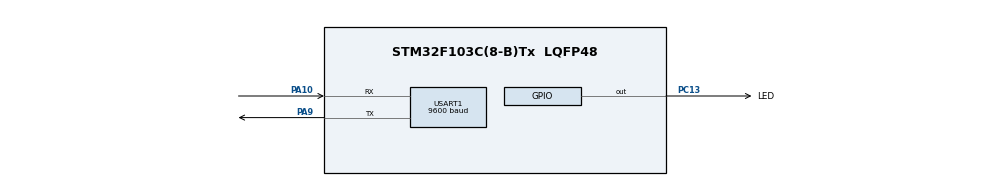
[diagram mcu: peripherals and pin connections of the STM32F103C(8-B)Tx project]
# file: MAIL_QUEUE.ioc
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FREERTOS.Queues01=Queue01,16,uint16_t,0,Dynamic,NULL,NULL
FREERTOS.Tasks01=defaultTask,0,128,StartDefaultTask,Default,NULL,Dynamic,NULL,NULL
FREERTOS.configUSE_NEWLIB_REENTRANT=1
Mcu.Family=STM32F1
Mcu.Name=STM32F103C(8-B)Tx
Mcu.Package=LQFP48
NVIC.PriorityGroup=NVIC_PRIORITYGROUP_4
NVIC.TIM4_IRQn=true\:15\:0\:false\:false\:true\:false\:false\:true\:true
NVIC.TimeBase=TIM4_IRQn
NVIC.TimeBaseIP=TIM4
NVIC.USART1_IRQn=true\:5\:0\:false\:false\:true\:true\:true\:true\:true
PA10.Mode=Asynchronous
PA10.Signal=USART1_RX
PA13.Mode=Serial_Wire
PA13.Signal=SYS_JTMS-SWDIO
PA14.Mode=Serial_Wire
PA14.Signal=SYS_JTCK-SWCLK
PA9.Mode=Asynchronous
PA9.Signal=USART1_TX
PC13-TAMPER-RTC.GPIO_Label=LED
PC13-TAMPER-RTC.Signal=GPIO_Output
PD0-OSC_IN.Mode=HSE-External-Oscillator
PD0-OSC_IN.Signal=RCC_OSC_IN
PD1-OSC_OUT.Mode=HSE-External-Oscillator
PD1-OSC_OUT.Signal=RCC_OSC_OUT
ProjectManager.HeapSize=0x200
ProjectManager.StackSize=0x400
ProjectManager.TargetToolchain=STM32CubeIDE
RCC.APB1Freq_Value=8000000
RCC.APB2Freq_Value=8000000
USART1.BaudRate=9600
USART1.VirtualMode=VM_ASYNC
VP_FREERTOS_VS_CMSIS_V1.Mode=CMSIS_V1
VP_SYS_VS_tim4.Mode=TIM4
board=custom

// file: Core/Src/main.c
/* USER CODE BEGIN Header */
/**
 ******************************************************************************
 * @file           : main.c
 * @brief          : Main program body
 ******************************************************************************
 * @attention
 *
 * Copyright (c) 2023 STMicroelectronics.
 * All rights reserved.
 *
 * This software is licensed under terms that can be found in the LICENSE file
 * in the root directory of this software component.
 * If no LICENSE file comes with this software, it is provided AS-IS.
 *
 ******************************************************************************
 */
/* USER CODE END Header */
#include "main.h"
#include "cmsis_os.h"

/* USER CODE BEGIN Includes */
#include "stdio.h"
#include "string.h"
/* USER CODE END Includes */

/* USER CODE BEGIN PTD */
typedef struct {
	char *name;
	uint8_t age;
	uint32_t salary;
} infor_t;
/* USER CODE END PTD */

UART_HandleTypeDef huart1;

osThreadId defaultTaskHandle;
osMessageQId Queue01Handle;
/* USER CODE BEGIN PV */
TaskHandle_t Task2Handle;
QueueHandle_t QueueTask02Handle;
/* USER CODE END PV */

void SystemClock_Config(void);
static void MX_GPIO_Init(void);
static void MX_USART1_UART_Init(void);
void StartDefaultTask(void const *argument);

/* USER CODE BEGIN PFP */
void Task2(void *parameter);
/* USER CODE END PFP */

/* USER CODE BEGIN 0 */
//--------------PRINTF-------------------------//
#if defined(__GNUC__)
int _write(int fd, char *ptr, int len) {
	HAL_UART_Transmit(&huart1, (uint8_t*) ptr, len, HAL_MAX_DELAY);
	return len;
}
#elif defined(__ICCARM__)#include "LowLevelIOInterface.h"

size_t __write(int handle,
  const unsigned char * buffer, size_t size) {
  HAL_UART_Transmit( & huart1, (uint8_t * ) buffer, size, HAL_MAX_DELAY);
  return size;
}
#elif defined(__CC_ARM)
int fputc(int ch, FILE * f) {
  HAL_UART_Transmit( & huart1, (uint8_t * ) & ch, 1, HAL_MAX_DELAY);
  return ch;
}
#endif

//-------------------- UART RECV -------------------
uint8_t DataRx;
void HAL_UART_RxCpltCallback(UART_HandleTypeDef *huart) {
	HAL_UART_Receive_IT(&huart1, &DataRx, 1);
	char DataFromISR[15] = "hello nha !";
	if (DataRx == 'a') {
		printf("Send data from ISR !\n");
		xQueueSendFromISR(QueueTask02Handle, (void* )&DataFromISR, NULL);
	}
}

/* USER CODE END 0 */

int main(void) {

	/* MCU Configuration--------------------------------------------------------*/

	/* Reset of all peripherals, Initializes the Flash interface and the Systick. */
	HAL_Init();

	/* Configure the system clock */
	SystemClock_Config();

	/* Initialize all configured peripherals */
	MX_GPIO_Init();
	MX_USART1_UART_Init();
	/* USER CODE BEGIN 2 */
	printf("Begin Program !!!");
	HAL_UART_Receive_IT(&huart1, &DataRx, 1);
	/* USER CODE END 2 */

	/* Create the queue(s) */
	/* definition and creation of Queue01 */
	osMailQDef(Queue01, 16, infor_t);		// cap phat bo nho vaf kieu du lieu
	Queue01Handle = osMailCreate(osMailQ(Queue01), NULL);// khoi tao mail queue

	/* USER CODE BEGIN RTOS_QUEUES */

	QueueTask02Handle = xQueueCreate(12, 15);
	/* add queues, ... */
	/* USER CODE END RTOS_QUEUES */

	/* Create the thread(s) */
	/* definition and creation of defaultTask */
	osThreadDef(defaultTask, StartDefaultTask, osPriorityNormal, 0, 128);
	defaultTaskHandle = osThreadCreate(osThread(defaultTask), NULL);

	/* USER CODE BEGIN RTOS_THREADS */
	xTaskCreate(Task2, "Task2", 128, NULL, osPriorityAboveNormal + 3,
			&Task2Handle);
	/* add threads, ... */
	/* USER CODE END RTOS_THREADS */

	/* Start scheduler */
	osKernelStart();

	/* We should never get here as control is now taken by the scheduler */
	/* Infinite loop */
	while (1) {

	}
}

void SystemClock_Config(void) {
	RCC_OscInitTypeDef RCC_OscInitStruct = { 0 };
	RCC_ClkInitTypeDef RCC_ClkInitStruct = { 0 };

	/** Initializes the RCC Oscillators according to the specified parameters
	 * in the RCC_OscInitTypeDef structure.
	 */
	RCC_OscInitStruct.OscillatorType = RCC_OSCILLATORTYPE_HSI;
	RCC_OscInitStruct.HSIState = RCC_HSI_ON;
	RCC_OscInitStruct.HSICalibrationValue = RCC_HSICALIBRATION_DEFAULT;
	RCC_OscInitStruct.PLL.PLLState = RCC_PLL_NONE;
	if (HAL_RCC_OscConfig(&RCC_OscInitStruct) != HAL_OK) {
		Error_Handler();
	}

	/** Initializes the CPU, AHB and APB buses clocks
	 */
	RCC_ClkInitStruct.ClockType = RCC_CLOCKTYPE_HCLK | RCC_CLOCKTYPE_SYSCLK
			| RCC_CLOCKTYPE_PCLK1 | RCC_CLOCKTYPE_PCLK2;
	RCC_ClkInitStruct.SYSCLKSource = RCC_SYSCLKSOURCE_HSI;
	RCC_ClkInitStruct.AHBCLKDivider = RCC_SYSCLK_DIV1;
	RCC_ClkInitStruct.APB1CLKDivider = RCC_HCLK_DIV1;
	RCC_ClkInitStruct.APB2CLKDivider = RCC_HCLK_DIV1;

	if (HAL_RCC_ClockConfig(&RCC_ClkInitStruct, FLASH_LATENCY_0) != HAL_OK) {
		Error_Handler();
	}
}

static void MX_USART1_UART_Init(void) {

	huart1.Instance = USART1;
	huart1.Init.BaudRate = 9600;
	huart1.Init.WordLength = UART_WORDLENGTH_8B;
	huart1.Init.StopBits = UART_STOPBITS_1;
	huart1.Init.Parity = UART_PARITY_NONE;
	huart1.Init.Mode = UART_MODE_TX_RX;
	huart1.Init.HwFlowCtl = UART_HWCONTROL_NONE;
	huart1.Init.OverSampling = UART_OVERSAMPLING_16;
	if (HAL_UART_Init(&huart1) != HAL_OK) {
		Error_Handler();
	}

}

static void MX_GPIO_Init(void) {
	GPIO_InitTypeDef GPIO_InitStruct = { 0 };

	/* GPIO Ports Clock Enable */
	__HAL_RCC_GPIOC_CLK_ENABLE();
	__HAL_RCC_GPIOD_CLK_ENABLE();
	__HAL_RCC_GPIOA_CLK_ENABLE();

	/*Configure GPIO pin Output Level */
	HAL_GPIO_WritePin(LED_GPIO_Port, LED_Pin, GPIO_PIN_RESET);

	/*Configure GPIO pin : LED_Pin */
	GPIO_InitStruct.Pin = LED_Pin;
	GPIO_InitStruct.Mode = GPIO_MODE_OUTPUT_PP;
	GPIO_InitStruct.Pull = GPIO_NOPULL;
	GPIO_InitStruct.Speed = GPIO_SPEED_FREQ_LOW;
	HAL_GPIO_Init(LED_GPIO_Port, &GPIO_InitStruct);

}

/* USER CODE BEGIN 4 */
void Task2(void *parameter) {
	char RecvDataISR[15];
	osEvent RecvDataTask;
	while (1) {
		printf("Waiting Data From Task\n");
		RecvDataTask = osMailGet(Queue01Handle, 100);// lay giu lieu tu QUEUE01
		infor_t *data = RecvDataTask.value.p;		// LAY GIA TRI TU CON TRO
		printf("Name : %s\nAge : %d\nSalary : %d\n", data->name, data->age,
				data->salary);
		osMailFree(Queue01Handle, data);		// ****GIAI PHONG BO NHO

//		printf("Waiting Data From ISR\n");
//		xQueueReceive(QueueTask02Handle, &RecvDataISR, osWaitForever);
//		printf("Data From ISR : %s\n", RecvDataISR);
		vTaskDelay(1000);
	}
}
/* USER CODE END 4 */

void StartDefaultTask(void const *argument) {
	/* USER CODE BEGIN 5 */
	infor_t *TaskData = osMailAlloc(Queue01Handle, 100);// PHAN PHAT BO NHO CHO MAIL QUEUE
	TaskData->name = "Tuan";
	TaskData->age = 21;
	TaskData->salary = 0;
	/* Infinite loop */
	for (;;) {
		HAL_GPIO_TogglePin(LED_GPIO_Port, LED_Pin);
		osMailPut(Queue01Handle, TaskData);	// TRUYEN GIA GIA TRI VAO MAIL QUEUE
		printf("Send Data From Task Defaul !\n");
		osDelay(1000);
	}
	/* USER CODE END 5 */
}

void HAL_TIM_PeriodElapsedCallback(TIM_HandleTypeDef *htim) {
	if (htim->Instance == TIM4) {
		HAL_IncTick();
	}
}

void Error_Handler(void) {
	__disable_irq();
	while (1) {
	}
}
